# LargeDummyDevice register map
File version: 1.0
Registers are 32-bit, read-write, no defined reset value unless marked. A register's access mark holds for its fields unless they carry their own. Offsets are from the block's base; [hi:lo] are bit positions.

## PERIPHERAL_92
Base 0x4005B000
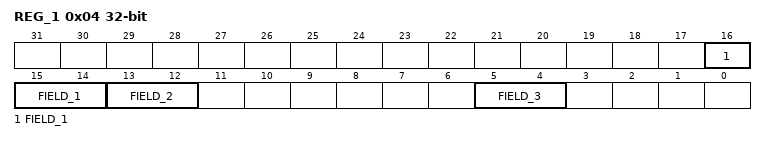
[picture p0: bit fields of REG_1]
0x04 REG_1 — Register 1
  [16:14] FIELD_1, [13:12] FIELD_2, [5:4] FIELD_3
0x08 REG_2 — Register 2
  [31] FIELD_10, [27:26] FIELD_1, [27:26] FIELD_11, [23:21] FIELD_3, [12:11] FIELD_7, [13:11] FIELD_12, [14:10] FIELD_2, [11:10] FIELD_5, [14:10] FIELD_6, [13:10] FIELD_8, [10] FIELD_9, [12:9] FIELD_4
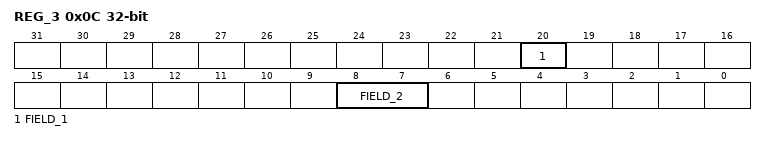
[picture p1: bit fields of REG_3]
0x0C REG_3 — Register 3
  [31:28] FIELD_8, [27] FIELD_3, [31:27] FIELD_4, [27:24] FIELD_2, [21] FIELD_7, [21:19] FIELD_1, [19] FIELD_5, [19:18] FIELD_6
0x10 REG_4 — Register 4
  [28:25] FIELD_5, [25] FIELD_9, [25] FIELD_12, [27:24] FIELD_2, [18] FIELD_11, [19:16] FIELD_3, [17:16] FIELD_7, [16:13] FIELD_1, [13:12] FIELD_6, [11:9] FIELD_10, [11:9] FIELD_13, [8:6] FIELD_8, [6:3] FIELD_14, [4:0] FIELD_4
0x14 REG_5 — Register 5
  [31:30] FIELD_11, [30:29] FIELD_3, [33:29] FIELD_7, [29] FIELD_21, [32:28] FIELD_6, [31:27] FIELD_19, [30:27] FIELD_22, [26] FIELD_16, [24] FIELD_2, [26:24] FIELD_12, [25:23] FIELD_17, [22] FIELD_20, [22:21] FIELD_9, [20:18] FIELD_5, [18] FIELD_14, [17] FIELD_8, [20:16] FIELD_15, [18:14] FIELD_4, [16:13] FIELD_13, [11:9] FIELD_18, [7:4] FIELD_1, [4:0] FIELD_10
0x18 REG_6 — Register 6
  [29:26] FIELD_1, [26] FIELD_4, [29:25] FIELD_3, [28:24] FIELD_2

## PERIPHERAL_98
Base 0x40061000
0x04 REG_1 — Register 1
  [33:30] FIELD_29, [32:29] FIELD_3, [33:29] FIELD_10, [33:29] FIELD_28, [28] FIELD_5, [31:27] FIELD_9, [27:26] FIELD_6, [27:26] FIELD_12, [29:26] FIELD_18, [25:23] FIELD_27, [25:22] FIELD_20, [25:21] FIELD_14, [24:20] FIELD_22, [17:15] FIELD_17, [15:13] FIELD_2, [16:12] FIELD_4, [14:12] FIELD_16, [15:11] FIELD_11, [12:11] FIELD_19, [15:11] FIELD_24, [12:9] FIELD_7, [9] FIELD_21, [6] FIELD_1, [8:5] FIELD_15, [6:2] FIELD_23, [1] FIELD_25, [0] FIELD_8, [0] FIELD_13, [2:0] FIELD_26
0x08 REG_2 — Register 2
  [31:30] FIELD_21, [32:30] FIELD_24, [32:29] FIELD_5, [32:29] FIELD_16, [32:28] FIELD_15, [25] FIELD_17, [24] FIELD_1, [25:23] FIELD_6, [22] FIELD_3, [22:20] FIELD_26, [21:19] FIELD_12, [22:18] FIELD_18, [19:18] FIELD_20, [21:17] FIELD_2, [18:16] FIELD_8, [18:15] FIELD_7, [16:15] FIELD_31, [14:13] FIELD_13, [16:12] FIELD_4, [15:12] FIELD_10, [11] FIELD_29, [11:9] FIELD_23, [9] FIELD_27, [10:7] FIELD_9, [8:7] FIELD_28, [6] FIELD_30, [8:4] FIELD_11, [5:3] FIELD_19, [5:2] FIELD_14, [4:1] FIELD_22, [4:1] FIELD_25
0x0C REG_3 — Register 3
  [20] FIELD_1, [8:7] FIELD_2
0x10 REG_4 — Register 4
  [34:30] FIELD_9, [32:29] FIELD_7, [29] FIELD_18, [30:28] FIELD_4, [29:27] FIELD_10, [28:27] FIELD_27, [26] FIELD_12, [26:24] FIELD_16, [26:22] FIELD_23, [21:19] FIELD_3, [19:18] FIELD_24, [16:15] FIELD_11, [15] FIELD_19, [18:14] FIELD_8, [14:13] FIELD_1, [15:13] FIELD_15, [16:12] FIELD_2, [13:11] FIELD_5, [15:11] FIELD_28, [13:11] FIELD_29, [12:10] FIELD_13, [10:9] FIELD_17, [11:8] FIELD_20, [3] FIELD_25, [4:2] FIELD_22, [2:1] FIELD_14, [4:1] FIELD_21, [5:1] FIELD_26, [1:0] FIELD_6
0x14 REG_5 — Register 5
  [32:30] FIELD_7, [24] FIELD_1, [21] FIELD_9, [20:19] FIELD_8, [17] FIELD_2, [13] FIELD_3, [12:9] FIELD_4, [10:8] FIELD_5, [5:2] FIELD_6
0x18 REG_6 — Register 6
  [34:31] FIELD_1, [31:30] FIELD_2, [32:29] FIELD_9, [33:29] FIELD_14, [29:27] FIELD_17, [31:27] FIELD_18, [26:24] FIELD_15, [25:23] FIELD_3, [26:22] FIELD_10, [24:21] FIELD_7, [22:20] FIELD_11, [20:19] FIELD_12, [23:19] FIELD_16, [19:18] FIELD_5, [15] FIELD_20, [17:13] FIELD_4, [14:11] FIELD_8, [8] FIELD_6, [7:4] FIELD_13, [2:1] FIELD_19
0x1C REG_7 — Register 7
  [32:31] FIELD_1, [28:26] FIELD_9, [26] FIELD_14, [26:25] FIELD_6, [25] FIELD_11, [27:24] FIELD_8, [24] FIELD_21, [25:23] FIELD_23, [22:18] FIELD_2, [19:17] FIELD_10, [18:17] FIELD_17, [18:16] FIELD_20, [19:15] FIELD_4, [15] FIELD_22, [18:14] FIELD_3, [14:13] FIELD_7, [17:13] FIELD_15, [11] FIELD_5, [14:11] FIELD_16, [13:10] FIELD_18, [3:2] FIELD_12, [3:2] FIELD_13, [6:2] FIELD_19, [6:2] FIELD_24
0x20 REG_8 — Register 8
  [31] FIELD_5, [30:27] FIELD_9, [25:24] FIELD_8, [20:17] FIELD_4, [20:17] FIELD_12, [17:16] FIELD_3, [15] FIELD_11, [15:14] FIELD_10, [11:10] FIELD_6, [11:8] FIELD_7, [11:7] FIELD_1, [6:5] FIELD_2

## PERIPHERAL_100
Base 0x40063000
0x04 REG_1 — Register 1
  [33:31] FIELD_12, [31:30] FIELD_19, [32:29] FIELD_10, [29:26] FIELD_9, [25] FIELD_2, [21:19] FIELD_13, [18:14] FIELD_6, [13] FIELD_16, [14:12] FIELD_1, [13:12] FIELD_15, [14:12] FIELD_20, [14:11] FIELD_5, [14:11] FIELD_8, [9] FIELD_11, [8] FIELD_18, [10:6] FIELD_14, [8:5] FIELD_17, [7:4] FIELD_3, [5:2] FIELD_4, [6:2] FIELD_7
0x08 REG_2 — Register 2
  [35:31] FIELD_7, [28:27] FIELD_5, [30:26] FIELD_2, [28:26] FIELD_12, [25:23] FIELD_13, [18:14] FIELD_1, [14] FIELD_6, [17:14] FIELD_8, [11:9] FIELD_3, [11:9] FIELD_4, [9:5] FIELD_9, [3:1] FIELD_10, [2:0] FIELD_11
0x0C REG_3 — Register 3
  [31] FIELD_2, [34:31] FIELD_23, [30:28] FIELD_4, [29:27] FIELD_15, [27] FIELD_19, [29:27] FIELD_25, [29:26] FIELD_21, [25:22] FIELD_6, [22:21] FIELD_10, [22:21] FIELD_26, [20] FIELD_1, [16:15] FIELD_20, [15:14] FIELD_9, [18:14] FIELD_12, [16:14] FIELD_22, [13] FIELD_13, [14:13] FIELD_14, [14:12] FIELD_17, [14:12] FIELD_18, [12:11] FIELD_3, [15:11] FIELD_8, [12:11] FIELD_11, [10] FIELD_5, [6] FIELD_7, [7:5] FIELD_27, [4:3] FIELD_24, [4:2] FIELD_16
0x10 REG_4 — Register 4
  [33:31] FIELD_9, [31:30] FIELD_14, [31:29] FIELD_16, [30:27] FIELD_10, [29:25] FIELD_15, [27:24] FIELD_4, [23:21] FIELD_13, [16:15] FIELD_5, [16:13] FIELD_3, [15:11] FIELD_7, [12:8] FIELD_12, [6:5] FIELD_1, [8:5] FIELD_11, [8:4] FIELD_2, [4:2] FIELD_6, [2:0] FIELD_8
0x14 REG_5 — Register 5
  [28:27] FIELD_4, [30:26] FIELD_6, [24] FIELD_5, [27:24] FIELD_7, [26:23] FIELD_2, [21:20] FIELD_1, [24:20] FIELD_11, [19:15] FIELD_9, [14] FIELD_12, [12:11] FIELD_13, [10:7] FIELD_10, [5:1] FIELD_8, [4:0] FIELD_3
0x18 REG_6 — Register 6
  [33:30] FIELD_9, [32:28] FIELD_7, [27] FIELD_5, [28:25] FIELD_10, [22:20] FIELD_3, [19:18] FIELD_4, [19:18] FIELD_8, [18] FIELD_12, [17:13] FIELD_1, [12] FIELD_2, [13:9] FIELD_11, [10:8] FIELD_13, [11:7] FIELD_6
